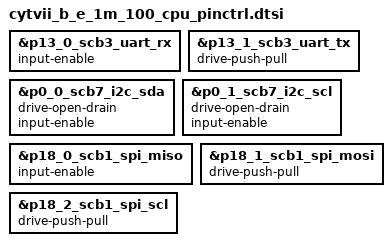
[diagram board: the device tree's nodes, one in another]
#include <zephyr/dt-bindings/input/input-event-codes.h>
#include <zephyr/dt-bindings/pinctrl/ifx_cat1-pinctrl.h>

&p13_0_scb3_uart_rx {
	input-enable;
};

&p13_1_scb3_uart_tx {
	drive-push-pull;
};

&p0_0_scb7_i2c_sda {
	drive-open-drain;
    input-enable;
};

&p0_1_scb7_i2c_scl {
    drive-open-drain;
    input-enable;
};

&p18_0_scb1_spi_miso {
	input-enable;
};

&p18_1_scb1_spi_mosi {
	drive-push-pull;
};

&p18_2_scb1_spi_scl {
	drive-push-pull;
};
